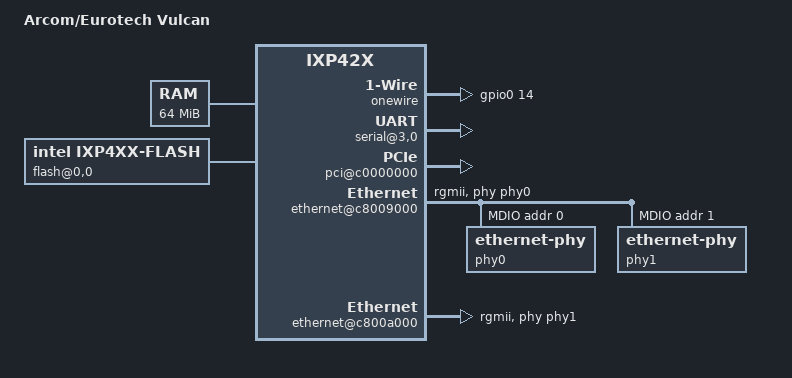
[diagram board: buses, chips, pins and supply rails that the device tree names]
/dts-v1/;
#include "intel-ixp42x.dtsi"
#include <dt-bindings/input/input.h>
/ {
	model = "Arcom/Eurotech Vulcan";
	compatible = "arcom,vulcan", "intel,ixp42x";
	#address-cells = <1>;
	#size-cells = <1>;
	memory@0 {
		device_type = "memory";
		reg = <0x00000000 0x4000000>;
	};
	chosen {
		bootargs = "console=ttyS0,115200n8 root=/dev/sda1 rw rootfstype=ext4 rootwait";
		stdout-path = "uart0:115200n8";
	};
	aliases {
		serial0 = &uart0;
	};
	onewire {
		compatible = "w1-gpio";
		gpios = <&gpio0 14 (GPIO_ACTIVE_HIGH|GPIO_OPEN_DRAIN)>;
	};
	soc {
		bus@c4000000 {
			flash@0,0 {
				compatible = "intel,ixp4xx-flash", "cfi-flash";
				bank-width = <2>;
				reg = <0 0x00000000 0x2000000>;
				intel,ixp4xx-eb-t3 = <3>;
				intel,ixp4xx-eb-byte-access-on-halfword = <1>;
				intel,ixp4xx-eb-write-enable = <1>;
				partitions {
					compatible = "redboot-fis";
					fis-index-block = <0x1ff>;
				};
			};
			sram@2,0 {
				compatible = "shared-dma-pool";
				device_type = "memory";
				reg = <2 0x00000000 0x40000>;
				no-map;
				intel,ixp4xx-eb-t3 = <1>;
				intel,ixp4xx-eb-t4 = <2>;
				intel,ixp4xx-eb-ahb-split-transfers = <1>;
				intel,ixp4xx-eb-write-enable = <1>;
				intel,ixp4xx-eb-byte-access = <1>;
			};
			serial@3,0 {
				compatible = "exar,xr16l2551", "ns8250";
				reg = <3 0x00000000 0x10>;
				interrupt-parent = <&gpio0>;
				interrupts = <4 IRQ_TYPE_LEVEL_LOW>;
				clock-frequency = <1843200>;
				intel,ixp4xx-eb-t3 = <3>;
				intel,ixp4xx-eb-cycle-type = <1>;  
				intel,ixp4xx-eb-write-enable = <1>;
				intel,ixp4xx-eb-byte-access = <1>;
			};
			gpio1: gpio@4,0 {
				compatible = "arcom,vulcan-gpio";
				reg = <4 0x00000000 0x1>;
				intel,ixp4xx-eb-write-enable = <1>;
				intel,ixp4xx-eb-byte-access = <1>;
			};
			watchdog@5,0 {
				compatible = "maxim,max6369";
				reg = <5 0x00000000 0x1>;
				intel,ixp4xx-eb-write-enable = <1>;
				intel,ixp4xx-eb-byte-access = <1>;
			};
		};
		pci@c0000000 {
			status = "okay";
			#interrupt-cells = <1>;
			interrupt-map-mask = <0xf800 0 0 7>;
			interrupt-map =
			<0x0800 0 0 1 &gpio0 2 IRQ_TYPE_LEVEL_LOW>,  
			<0x0800 0 0 2 &gpio0 2 IRQ_TYPE_LEVEL_LOW>,  
			<0x0800 0 0 3 &gpio0 2 IRQ_TYPE_LEVEL_LOW>,  
			<0x0800 0 0 4 &gpio0 2 IRQ_TYPE_LEVEL_LOW>,  
			<0x1000 0 0 1 &gpio0 3 IRQ_TYPE_LEVEL_LOW>,  
			<0x1000 0 0 2 &gpio0 3 IRQ_TYPE_LEVEL_LOW>,  
			<0x1000 0 0 3 &gpio0 3 IRQ_TYPE_LEVEL_LOW>,  
			<0x1000 0 0 4 &gpio0 3 IRQ_TYPE_LEVEL_LOW>;  
		};
		ethernet@c8009000 {
			status = "okay";
			queue-rx = <&qmgr 3>;
			queue-txready = <&qmgr 20>;
			phy-mode = "rgmii";
			phy-handle = <&phy0>;
			mdio {
				#address-cells = <1>;
				#size-cells = <0>;
				phy0: ethernet-phy@0 {
					reg = <0>;
				};
				phy1: ethernet-phy@1 {
					reg = <1>;
				};
			};
		};
		ethernet@c800a000 {
			status = "okay";
			queue-rx = <&qmgr 4>;
			queue-txready = <&qmgr 21>;
			phy-mode = "rgmii";
			phy-handle = <&phy1>;
		};
	};
};
